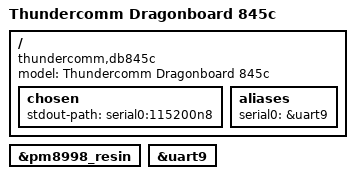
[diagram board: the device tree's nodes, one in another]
// SPDX-License-Identifier: GPL-2.0+
/*
 * Qualcomm Robotics RB3 Development (dragonboard845c) board device
 * tree source
 *
 * (C) Copyright 2022 Sumit Garg <sumit.garg@linaro.org>
 */

/dts-v1/;

#include "sdm845.dtsi"
#include "pm8998.dtsi"

/ {
	model = "Thundercomm Dragonboard 845c";
	compatible = "thundercomm,db845c", "qcom,sdm845";

	chosen {
		stdout-path = "serial0:115200n8";
	};

	aliases {
		serial0 = &uart9;
	};
};

&pm8998_resin {
	status = "okay";
};

&uart9 {
	status = "okay";
};
